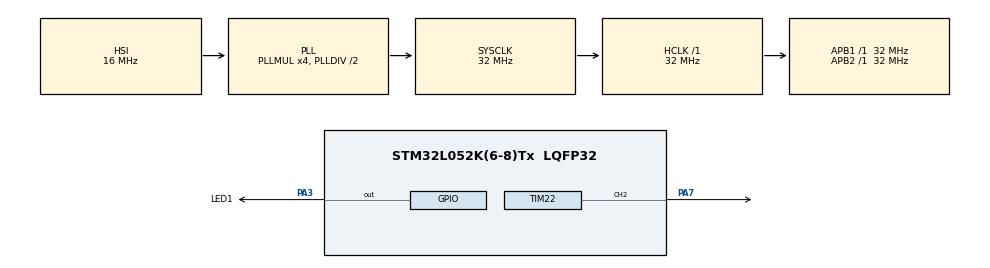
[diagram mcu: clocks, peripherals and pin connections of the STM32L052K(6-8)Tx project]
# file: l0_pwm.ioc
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Mcu.Family=STM32L0
RCC.MSI_VALUE=2097000
RCC.SYSCLKSource=RCC_SYSCLKSOURCE_PLLCLK
ProjectManager.StackSize=0x400
TIM22.Period=1000-1
PA13.Signal=SYS_SWDIO
RCC.HSI16_VALUE=16000000
ProjectManager.TargetToolchain=STM32CubeIDE
SH.S_TIM22_CH2.0=TIM22_CH2,PWM Generation2 CH2
RCC.HCLKFreq_Value=32000000
RCC.APB2TimFreq_Value=32000000
TIM22.Prescaler=32-1
TIM22.Channel-PWM\ Generation2\ CH2=TIM_CHANNEL_2
RCC.LSE_VALUE=32768
RCC.AHBFreq_Value=32000000
VP_TIM22_VS_ClockSourceINT.Mode=Internal
TIM22.Pulse-PWM\ Generation2\ CH2=500
board=custom
RCC.VCOOutputFreq_Value=64000000
RCC.PLLMUL=RCC_PLLMUL_4
RCC.APB2Freq_Value=32000000
PA14.Mode=Serial_Wire
PA13.Mode=Serial_Wire
Mcu.Name=STM32L052K(6-8)Tx
RCC.SYSCLKFreq_VALUE=32000000
Mcu.Package=LQFP32
PA14.Signal=SYS_SWCLK
ProjectManager.HeapSize=0x200
RCC.HSI_VALUE=16000000
RCC.APB1TimFreq_Value=32000000
RCC.APB1Freq_Value=32000000
RCC.HSI48_VALUE=48000000
PA3.GPIO_Label=LED1
PA3.Signal=GPIO_Output
PA7.Signal=S_TIM22_CH2

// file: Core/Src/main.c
/* USER CODE BEGIN Header */
/**
  ******************************************************************************
  * @file           : main.c
  * @brief          : Main program body
  ******************************************************************************
  * @attention
  *
  * <h2><center>&copy; Copyright (c) 2021 STMicroelectronics.
  * All rights reserved.</center></h2>
  *
  * This software component is licensed by ST under BSD 3-Clause license,
  * the "License"; You may not use this file except in compliance with the
  * License. You may obtain a copy of the License at:
  *                        opensource.org/licenses/BSD-3-Clause
  *
  ******************************************************************************
  */
/* USER CODE END Header */
#include "main.h"

TIM_HandleTypeDef htim22;

void SystemClock_Config(void);
static void MX_GPIO_Init(void);
static void MX_TIM22_Init(void);

int main(void)
{

  /* MCU Configuration--------------------------------------------------------*/

  /* Reset of all peripherals, Initializes the Flash interface and the Systick. */
  HAL_Init();

  /* Configure the system clock */
  SystemClock_Config();

  /* Initialize all configured peripherals */
  MX_GPIO_Init();
  MX_TIM22_Init();
  /* USER CODE BEGIN 2 */
  HAL_TIM_PWM_Start(&htim22, TIM_CHANNEL_2);

  /* USER CODE END 2 */

  /* Infinite loop */
  /* USER CODE BEGIN WHILE */
  while (1)
  {
	  static uint32_t last;
	  uint32_t now = HAL_GetTick();
	  static uint32_t pwmValue = 0;

	  if(now - last > 100){
		  pwmValue += 50;
		  if(pwmValue > 1000){
			  pwmValue = 0;
		  }
		  htim22.Instance->CCR2 = pwmValue;
		  //__HAL_TIM_SET_COMPARE(&htim22, TIM_CHANNEL_2, pwmValue);
		  //HAL_GPIO_TogglePin(LED1_GPIO_Port, LED1_Pin);

		  last = now;
	  }

    /* USER CODE END WHILE */

  }
}

void SystemClock_Config(void)
{
  RCC_OscInitTypeDef RCC_OscInitStruct = {0};
  RCC_ClkInitTypeDef RCC_ClkInitStruct = {0};

  /** Configure the main internal regulator output voltage
  */
  __HAL_PWR_VOLTAGESCALING_CONFIG(PWR_REGULATOR_VOLTAGE_SCALE1);
  /** Initializes the RCC Oscillators according to the specified parameters
  * in the RCC_OscInitTypeDef structure.
  */
  RCC_OscInitStruct.OscillatorType = RCC_OSCILLATORTYPE_HSI;
  RCC_OscInitStruct.HSIState = RCC_HSI_ON;
  RCC_OscInitStruct.HSICalibrationValue = RCC_HSICALIBRATION_DEFAULT;
  RCC_OscInitStruct.PLL.PLLState = RCC_PLL_ON;
  RCC_OscInitStruct.PLL.PLLSource = RCC_PLLSOURCE_HSI;
  RCC_OscInitStruct.PLL.PLLMUL = RCC_PLLMUL_4;
  RCC_OscInitStruct.PLL.PLLDIV = RCC_PLLDIV_2;
  if (HAL_RCC_OscConfig(&RCC_OscInitStruct) != HAL_OK)
  {
    Error_Handler();
  }
  /** Initializes the CPU, AHB and APB buses clocks
  */
  RCC_ClkInitStruct.ClockType = RCC_CLOCKTYPE_HCLK|RCC_CLOCKTYPE_SYSCLK
                              |RCC_CLOCKTYPE_PCLK1|RCC_CLOCKTYPE_PCLK2;
  RCC_ClkInitStruct.SYSCLKSource = RCC_SYSCLKSOURCE_PLLCLK;
  RCC_ClkInitStruct.AHBCLKDivider = RCC_SYSCLK_DIV1;
  RCC_ClkInitStruct.APB1CLKDivider = RCC_HCLK_DIV1;
  RCC_ClkInitStruct.APB2CLKDivider = RCC_HCLK_DIV1;

  if (HAL_RCC_ClockConfig(&RCC_ClkInitStruct, FLASH_LATENCY_1) != HAL_OK)
  {
    Error_Handler();
  }
}

static void MX_TIM22_Init(void)
{

  TIM_ClockConfigTypeDef sClockSourceConfig = {0};
  TIM_MasterConfigTypeDef sMasterConfig = {0};
  TIM_OC_InitTypeDef sConfigOC = {0};

  htim22.Instance = TIM22;
  htim22.Init.Prescaler = 32-1;
  htim22.Init.CounterMode = TIM_COUNTERMODE_UP;
  htim22.Init.Period = 1000-1;
  htim22.Init.ClockDivision = TIM_CLOCKDIVISION_DIV1;
  htim22.Init.AutoReloadPreload = TIM_AUTORELOAD_PRELOAD_DISABLE;
  if (HAL_TIM_Base_Init(&htim22) != HAL_OK)
  {
    Error_Handler();
  }
  sClockSourceConfig.ClockSource = TIM_CLOCKSOURCE_INTERNAL;
  if (HAL_TIM_ConfigClockSource(&htim22, &sClockSourceConfig) != HAL_OK)
  {
    Error_Handler();
  }
  if (HAL_TIM_PWM_Init(&htim22) != HAL_OK)
  {
    Error_Handler();
  }
  sMasterConfig.MasterOutputTrigger = TIM_TRGO_RESET;
  sMasterConfig.MasterSlaveMode = TIM_MASTERSLAVEMODE_DISABLE;
  if (HAL_TIMEx_MasterConfigSynchronization(&htim22, &sMasterConfig) != HAL_OK)
  {
    Error_Handler();
  }
  sConfigOC.OCMode = TIM_OCMODE_PWM1;
  sConfigOC.Pulse = 500;
  sConfigOC.OCPolarity = TIM_OCPOLARITY_HIGH;
  sConfigOC.OCFastMode = TIM_OCFAST_DISABLE;
  if (HAL_TIM_PWM_ConfigChannel(&htim22, &sConfigOC, TIM_CHANNEL_2) != HAL_OK)
  {
    Error_Handler();
  }
  HAL_TIM_MspPostInit(&htim22);

}

static void MX_GPIO_Init(void)
{
  GPIO_InitTypeDef GPIO_InitStruct = {0};

  /* GPIO Ports Clock Enable */
  __HAL_RCC_GPIOA_CLK_ENABLE();

  /*Configure GPIO pin Output Level */
  HAL_GPIO_WritePin(LED1_GPIO_Port, LED1_Pin, GPIO_PIN_RESET);

  /*Configure GPIO pin : LED1_Pin */
  GPIO_InitStruct.Pin = LED1_Pin;
  GPIO_InitStruct.Mode = GPIO_MODE_OUTPUT_PP;
  GPIO_InitStruct.Pull = GPIO_NOPULL;
  GPIO_InitStruct.Speed = GPIO_SPEED_FREQ_LOW;
  HAL_GPIO_Init(LED1_GPIO_Port, &GPIO_InitStruct);

}

void Error_Handler(void)
{
  __disable_irq();
  while (1)
  {
  }
}

/************************ (C) COPYRIGHT STMicroelectronics *****END OF FILE****/
